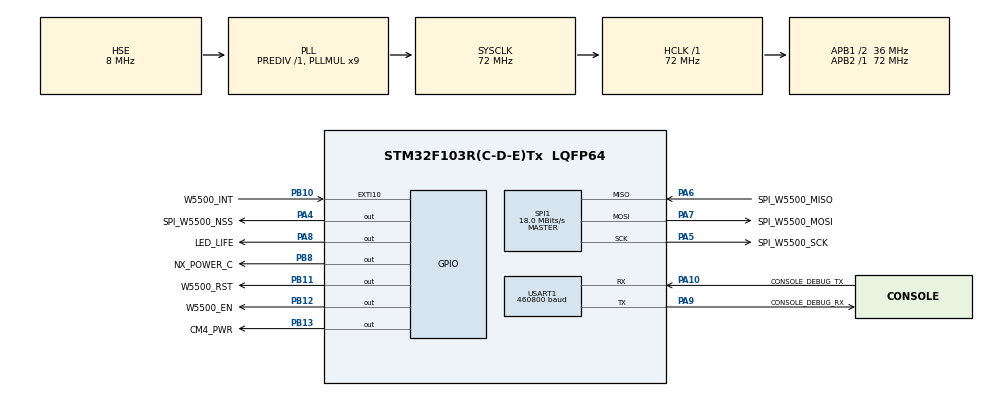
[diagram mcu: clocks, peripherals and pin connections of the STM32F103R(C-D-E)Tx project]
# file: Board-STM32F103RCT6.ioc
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FREERTOS.Tasks01=defaultTask,24,128,StartDefaultTask,Default,NULL,Dynamic,NULL,NULL
FREERTOS.configCHECK_FOR_STACK_OVERFLOW=1
FREERTOS.configTIMER_TASK_PRIORITY=7
FREERTOS.configTOTAL_HEAP_SIZE=32768
FREERTOS.configUSE_MALLOC_FAILED_HOOK=1
FREERTOS.configUSE_NEWLIB_REENTRANT=1
IWDG.Prescaler=IWDG_PRESCALER_256
Mcu.Family=STM32F1
Mcu.Name=STM32F103R(C-D-E)Tx
Mcu.Package=LQFP64
NVIC.EXTI15_10_IRQn=true\:6\:0\:true\:false\:true\:true\:true\:true\:true
NVIC.PriorityGroup=NVIC_PRIORITYGROUP_4
NVIC.USART1_IRQn=true\:5\:0\:false\:false\:true\:true\:true\:true\:true
PA10.GPIO_Label=CONSOLE_DEBUG_TX
PA10.Mode=Asynchronous
PA10.Signal=USART1_RX
PA13.Mode=Serial_Wire
PA13.Signal=SYS_JTMS-SWDIO
PA14.Mode=Serial_Wire
PA14.Signal=SYS_JTCK-SWCLK
PA4.GPIO_Label=SPI_W5500_NSS
PA4.Signal=GPIO_Output
PA5.GPIO_Label=SPI_W5500_SCK
PA5.Mode=Full_Duplex_Master
PA5.Signal=SPI1_SCK
PA6.GPIO_Label=SPI_W5500_MISO
PA6.Mode=Full_Duplex_Master
PA6.Signal=SPI1_MISO
PA7.GPIO_Label=SPI_W5500_MOSI
PA7.Mode=Full_Duplex_Master
PA7.Signal=SPI1_MOSI
PA8.GPIO_Label=LED_LIFE
PA8.Signal=GPIO_Output
PA9.GPIO_Label=CONSOLE_DEBUG_RX
PA9.Mode=Asynchronous
PA9.Signal=USART1_TX
PB10.GPIO_Label=W5500_INT
PB10.GPIO_ModeDefaultEXTI=GPIO_MODE_IT_RISING_FALLING
PB10.GPIO_PuPd=GPIO_PULLUP
PB10.Signal=GPXTI10
PB11.GPIO_Label=W5500_RST
PB11.Signal=GPIO_Output
PB12.GPIO_Label=W5500_EN
PB12.GPIO_ModeDefaultOutputPP=GPIO_MODE_OUTPUT_PP
PB12.GPIO_PuPd=GPIO_NOPULL
PB12.Signal=GPIO_Output
PB13.GPIO_Label=CM4_PWR
PB13.GPIO_ModeDefaultOutputPP=GPIO_MODE_OUTPUT_OD
PB13.GPIO_PuPd=GPIO_NOPULL
PB13.Signal=GPIO_Output
PB8.GPIO_Label=NX_POWER_C
PB8.GPIO_ModeDefaultOutputPP=GPIO_MODE_OUTPUT_OD
PB8.GPIO_PuPd=GPIO_NOPULL
PB8.Signal=GPIO_Output
PC14-OSC32_IN.Mode=LSE-External-Oscillator
PC14-OSC32_IN.Signal=RCC_OSC32_IN
PC15-OSC32_OUT.Mode=LSE-External-Oscillator
PC15-OSC32_OUT.Signal=RCC_OSC32_OUT
PD0-OSC_IN.Mode=HSE-External-Oscillator
PD0-OSC_IN.Signal=RCC_OSC_IN
PD1-OSC_OUT.Mode=HSE-External-Oscillator
PD1-OSC_OUT.Signal=RCC_OSC_OUT
ProjectManager.HeapSize=0x200
ProjectManager.StackSize=0x400
ProjectManager.TargetToolchain=STM32CubeIDE
RCC.AHBFreq_Value=72000000
RCC.APB1CLKDivider=RCC_HCLK_DIV2
RCC.APB1Freq_Value=36000000
RCC.APB1TimFreq_Value=72000000
RCC.APB2Freq_Value=72000000
RCC.APB2TimFreq_Value=72000000
RCC.HCLKFreq_Value=72000000
RCC.PLLMUL=RCC_PLL_MUL9
RCC.PLLSourceVirtual=RCC_PLLSOURCE_HSE
RCC.SYSCLKFreq_VALUE=72000000
RCC.SYSCLKSource=RCC_SYSCLKSOURCE_PLLCLK
RCC.USBFreq_Value=72000000
SPI1.BaudRatePrescaler=SPI_BAUDRATEPRESCALER_4
SPI1.CalculateBaudRate=18.0 MBits/s
SPI1.Direction=SPI_DIRECTION_2LINES
SPI1.Mode=SPI_MODE_MASTER
SPI1.VirtualType=VM_MASTER
USART1.BaudRate=460800
USART1.VirtualMode=VM_ASYNC
VP_FREERTOS_VS_CMSIS_V2.Mode=CMSIS_V2
VP_IWDG_VS_IWDG.Mode=IWDG_Activate
board=custom

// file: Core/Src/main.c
/* USER CODE BEGIN Header */
/**
  ******************************************************************************
  * @file           : main.c
  * @brief          : Main program body
  ******************************************************************************
  * @attention
  *
  * Copyright (c) 2024 STMicroelectronics.
  * All rights reserved.
  *
  * This software is licensed under terms that can be found in the LICENSE file
  * in the root directory of this software component.
  * If no LICENSE file comes with this software, it is provided AS-IS.
  *
  ******************************************************************************
  */
/* USER CODE END Header */
#include "main.h"
#include "cmsis_os.h"
#include "iwdg.h"
#include "spi.h"
#include "usart.h"
#include "gpio.h"

/* USER CODE BEGIN Includes */
#include <stdio.h>
#include <stdbool.h>
#include <stdint.h>

#include "testDHCP.h"
/* USER CODE END Includes */

void SystemClock_Config(void);
void MX_FREERTOS_Init(void);

int main(void)
{

  /* MCU Configuration--------------------------------------------------------*/

  /* Reset of all peripherals, Initializes the Flash interface and the Systick. */
  HAL_Init();

  /* Configure the system clock */
  SystemClock_Config();

  /* Initialize all configured peripherals */
  MX_GPIO_Init();
  MX_IWDG_Init();
  MX_USART1_UART_Init();
  MX_SPI1_Init();
  /* USER CODE BEGIN 2 */
#if 1
  /* USER CODE END 2 */

  /* Init scheduler */
  osKernelInitialize();

  /* Call init function for freertos objects (in cmsis_os2.c) */
  MX_FREERTOS_Init();

  /* Start scheduler */
  osKernelStart();

  /* We should never get here as control is now taken by the scheduler */

  /* Infinite loop */
  /* USER CODE BEGIN WHILE */
#endif

  while (1)
  {
    /* USER CODE END WHILE */

    /* USER CODE BEGIN 3 */
    osDelay(portMAX_DELAY);
  }
  /* USER CODE END 3 */
}

void SystemClock_Config(void)
{
  RCC_OscInitTypeDef RCC_OscInitStruct = {0};
  RCC_ClkInitTypeDef RCC_ClkInitStruct = {0};

  /** Initializes the RCC Oscillators according to the specified parameters
  * in the RCC_OscInitTypeDef structure.
  */
  RCC_OscInitStruct.OscillatorType = RCC_OSCILLATORTYPE_LSI|RCC_OSCILLATORTYPE_HSE;
  RCC_OscInitStruct.HSEState = RCC_HSE_ON;
  RCC_OscInitStruct.HSEPredivValue = RCC_HSE_PREDIV_DIV1;
  RCC_OscInitStruct.HSIState = RCC_HSI_ON;
  RCC_OscInitStruct.LSIState = RCC_LSI_ON;
  RCC_OscInitStruct.PLL.PLLState = RCC_PLL_ON;
  RCC_OscInitStruct.PLL.PLLSource = RCC_PLLSOURCE_HSE;
  RCC_OscInitStruct.PLL.PLLMUL = RCC_PLL_MUL9;
  if (HAL_RCC_OscConfig(&RCC_OscInitStruct) != HAL_OK)
  {
    Error_Handler();
  }

  /** Initializes the CPU, AHB and APB buses clocks
  */
  RCC_ClkInitStruct.ClockType = RCC_CLOCKTYPE_HCLK|RCC_CLOCKTYPE_SYSCLK
                              |RCC_CLOCKTYPE_PCLK1|RCC_CLOCKTYPE_PCLK2;
  RCC_ClkInitStruct.SYSCLKSource = RCC_SYSCLKSOURCE_PLLCLK;
  RCC_ClkInitStruct.AHBCLKDivider = RCC_SYSCLK_DIV1;
  RCC_ClkInitStruct.APB1CLKDivider = RCC_HCLK_DIV2;
  RCC_ClkInitStruct.APB2CLKDivider = RCC_HCLK_DIV1;

  if (HAL_RCC_ClockConfig(&RCC_ClkInitStruct, FLASH_LATENCY_2) != HAL_OK)
  {
    Error_Handler();
  }
}

void Error_Handler(void)
{
  __disable_irq();
  while (1)
  {
  }
}

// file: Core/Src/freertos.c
/* USER CODE BEGIN Header */
/**
  ******************************************************************************
  * File Name          : freertos.c
  * Description        : Code for freertos applications
  ******************************************************************************
  * @attention
  *
  * Copyright (c) 2024 STMicroelectronics.
  * All rights reserved.
  *
  * This software is licensed under terms that can be found in the LICENSE file
  * in the root directory of this software component.
  * If no LICENSE file comes with this software, it is provided AS-IS.
  *
  ******************************************************************************
  */
/* USER CODE END Header */

#include "FreeRTOS.h"
#include "task.h"
#include "main.h"
#include "cmsis_os.h"

/* USER CODE BEGIN Includes */
#include "app.h"
#include "sys_dbg.h"
/* USER CODE END Includes */

/* Definitions for defaultTask */
osThreadId_t defaultTaskHandle;
const osThreadAttr_t defaultTask_attributes = {
  .name = "defaultTask",
  .stack_size = 128 * 4,
  .priority = (osPriority_t) osPriorityNormal,
};

void StartDefaultTask(void *argument);

void MX_FREERTOS_Init(void); /* (MISRA C 2004 rule 8.1) */

/* Hook prototypes */
void vApplicationStackOverflowHook(xTaskHandle xTask, signed char *pcTaskName);
void vApplicationMallocFailedHook(void);

/* USER CODE BEGIN 4 */
void vApplicationStackOverflowHook(xTaskHandle xTask, signed char *pcTaskName)
{
   /* Run time stack overflow checking is performed if
   configCHECK_FOR_STACK_OVERFLOW is defined to 1 or 2. This hook function is
   called if a stack overflow is detected. */
   FATAL("StackOverflow");
}
/* USER CODE END 4 */

/* USER CODE BEGIN 5 */
void vApplicationMallocFailedHook(void)
{
   /* vApplicationMallocFailedHook() will only be called if
   configUSE_MALLOC_FAILED_HOOK is set to 1 in FreeRTOSConfig.h. It is a hook
   function that will get called if a call to pvPortMalloc() fails.
   pvPortMalloc() is called internally by the kernel whenever a task, queue,
   timer or semaphore is created. It is also called by various parts of the
   demo application. If heap_1.c or heap_2.c are used, then the size of the
   heap available to pvPortMalloc() is defined by configTOTAL_HEAP_SIZE in
   FreeRTOSConfig.h, and the xPortGetFreeHeapSize() API function can be used
   to query the size of free heap space that remains (although it does not
   provide information on how the remaining heap might be fragmented). */
   FATAL("MallocFailed");
}
/* USER CODE END 5 */

void MX_FREERTOS_Init(void) {
  /* USER CODE BEGIN Init */
  appInit();
  /* USER CODE END Init */

  /* Create the thread(s) */
  /* creation of defaultTask */
  defaultTaskHandle = osThreadNew(StartDefaultTask, NULL, &defaultTask_attributes);

}

void StartDefaultTask(void *argument)
{
  /* USER CODE BEGIN StartDefaultTask */
  vTaskDelete(NULL);
	/* Infinite loop */
  for(;;)
  {
    osDelay(portMAX_DELAY);
  }
  /* USER CODE END StartDefaultTask */
}
